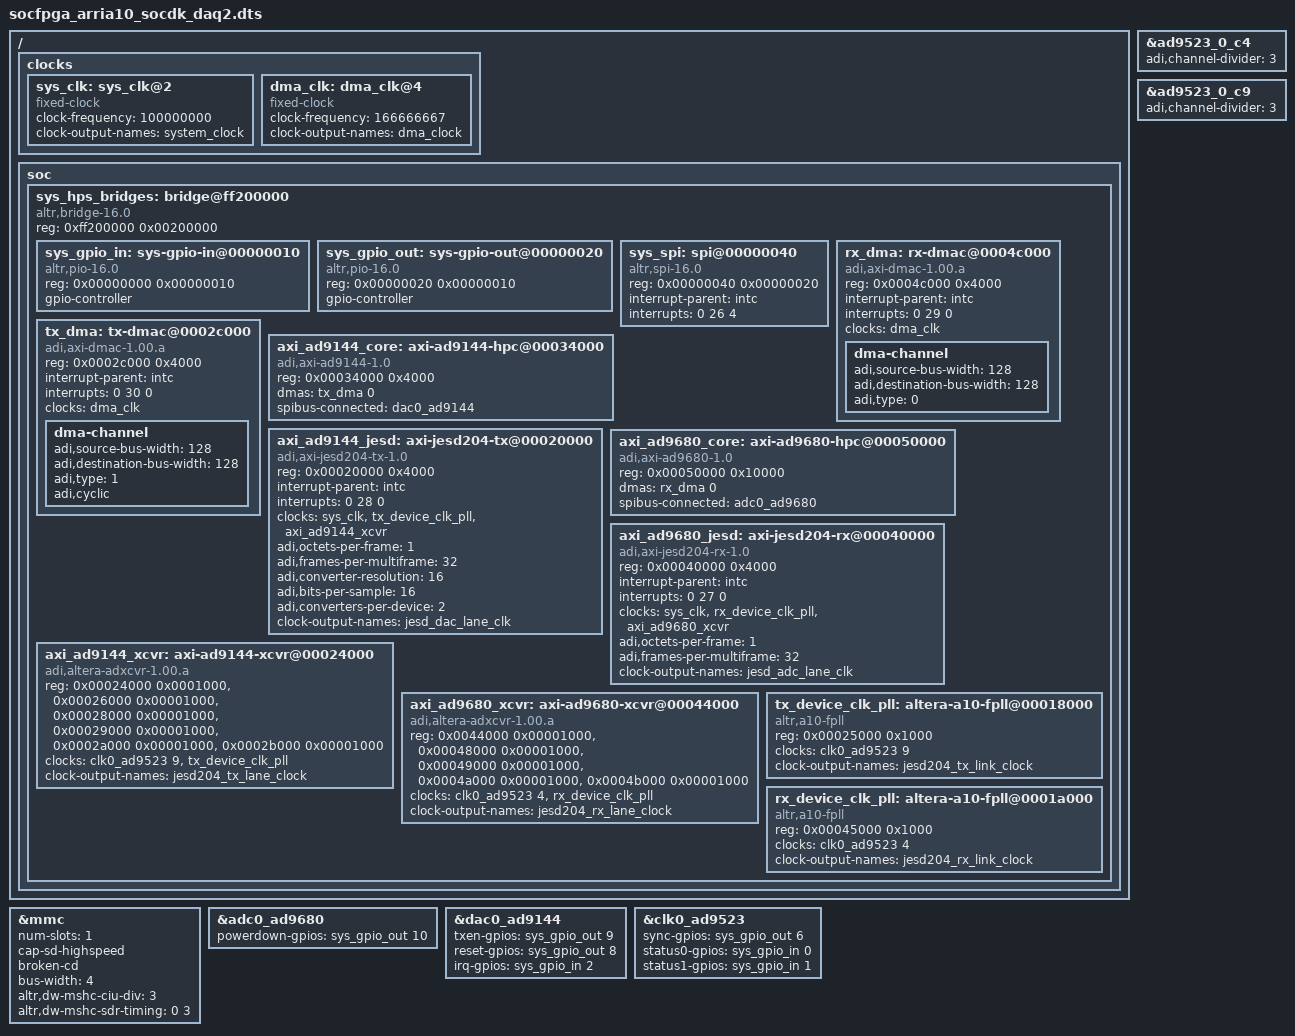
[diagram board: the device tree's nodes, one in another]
/dts-v1/;
#include "socfpga_arria10_socdk.dtsi"

&mmc {
	status = "okay";
	num-slots = <1>;
	cap-sd-highspeed;
	broken-cd;
	bus-width = <4>;
	altr,dw-mshc-ciu-div = <3>;
	altr,dw-mshc-sdr-timing = <0 3>;
};

/ {
	clocks {
		sys_clk: sys_clk@2 {
			#clock-cells = <0>;
			compatible = "fixed-clock";
			clock-frequency = <100000000>;
			clock-output-names = "system_clock";
		};

		dma_clk: dma_clk@4 {
			#clock-cells = <0>;
			compatible = "fixed-clock";
			clock-frequency = <166666667>;
			clock-output-names = "dma_clock";
		};
	};

	soc {
		sys_hps_bridges: bridge@ff200000 {
			compatible = "altr,bridge-16.0", "simple-bus";
			reg = <0xff200000 0x00200000>;
			#address-cells = <1>;
			#size-cells = <1>;
			ranges = <0x00000000 0xff200000 0x00200000>;

			sys_gpio_in: sys-gpio-in@00000010 {
				compatible = "altr,pio-16.0", "altr,pio-1.0";
				reg = <0x00000000 0x00000010>;
				#gpio-cells = <2>;
				gpio-controller;
			};

			sys_gpio_out: sys-gpio-out@00000020 {
				compatible = "altr,pio-16.0", "altr,pio-1.0";
				reg = <0x00000020 0x00000010>;
				#gpio-cells = <2>;
				gpio-controller;
			};

			sys_spi: spi@00000040 {
				compatible = "altr,spi-16.0", "altr,spi-1.0";
				reg = <0x00000040 0x00000020>;
				interrupt-parent = <&intc>;
				interrupts = <0 26 4>;
				#address-cells = <0x1>;
				#size-cells = <0x0>;
			};

			rx_dma: rx-dmac@0004c000 {
				compatible = "adi,axi-dmac-1.00.a";
				reg = <0x0004c000 0x4000>;
				#dma-cells = <1>;
				interrupt-parent = <&intc>;
				interrupts = <0 29 0>;
				clocks = <&dma_clk>;

				dma-channel {
					adi,source-bus-width = <128>;
					adi,destination-bus-width = <128>;
					adi,type = <0>;
				};
			};

			tx_dma: tx-dmac@0002c000 {
				compatible = "adi,axi-dmac-1.00.a";
				reg = <0x0002c000 0x4000>;
				#dma-cells = <1>;
				interrupt-parent = <&intc>;
				interrupts = <0 30 0>;
				clocks = <&dma_clk>;

				dma-channel {
					adi,source-bus-width = <128>;
					adi,destination-bus-width = <128>;
					adi,type = <1>;
					adi,cyclic;
				};
			};

			axi_ad9144_core: axi-ad9144-hpc@00034000 {
				compatible = "adi,axi-ad9144-1.0";
				reg = <0x00034000 0x4000>;
				dmas = <&tx_dma 0>;
				dma-names = "tx";
				spibus-connected = <&dac0_ad9144>;
//				adi,axi-pl-fifo-enable;
			};

			axi_ad9144_jesd: axi-jesd204-tx@00020000 {
				compatible = "adi,axi-jesd204-tx-1.0";
				reg = <0x00020000 0x4000>;

				interrupt-parent = <&intc>;
				interrupts = <0 28 0>;

				clocks = <&sys_clk>, <&tx_device_clk_pll>, <&axi_ad9144_xcvr>;
				clock-names = "s_axi_aclk", "device_clk", "lane_clk";

				adi,octets-per-frame = <1>;
				adi,frames-per-multiframe = <32>;
				adi,converter-resolution = <16>;
				adi,bits-per-sample = <16>;
				adi,converters-per-device = <2>;

				#clock-cells = <0>;
				clock-output-names = "jesd_dac_lane_clk";
			};

			axi_ad9680_core: axi-ad9680-hpc@00050000 {
				compatible = "adi,axi-ad9680-1.0";
				reg = <0x00050000 0x10000>;
				dmas = <&rx_dma 0>;
				dma-names = "rx";
				spibus-connected = <&adc0_ad9680>;
			};

			axi_ad9680_jesd: axi-jesd204-rx@00040000 {
				compatible = "adi,axi-jesd204-rx-1.0";
				reg = <0x00040000 0x4000>;

				interrupt-parent = <&intc>;
				interrupts = <0 27 0>;

				clocks = <&sys_clk>, <&rx_device_clk_pll>, <&axi_ad9680_xcvr>;
				clock-names = "s_axi_aclk", "device_clk", "lane_clk";

				adi,octets-per-frame = <1>;
				adi,frames-per-multiframe = <32>;

				#clock-cells = <0>;
				clock-output-names = "jesd_adc_lane_clk";
			};

			axi_ad9144_xcvr: axi-ad9144-xcvr@00024000 {
				compatible = "adi,altera-adxcvr-1.00.a";
				reg = <0x00024000 0x0001000>,
					<0x00026000 0x00001000>,
					<0x00028000 0x00001000>,
					<0x00029000 0x00001000>,
					<0x0002a000 0x00001000>,
					<0x0002b000 0x00001000>;
				reg-names = "adxcvr", "atx-pll", "adxcfg-0", "adxcfg-1", "adxcfg-2", "adxcfg-3";

				#clock-cells = <0>;
				clocks = <&clk0_ad9523 9>, <&tx_device_clk_pll>;
				clock-names = "ref", "link";
				clock-output-names = "jesd204_tx_lane_clock";
			};

			axi_ad9680_xcvr: axi-ad9680-xcvr@00044000 {
				compatible = "adi,altera-adxcvr-1.00.a";
				reg = <0x0044000 0x00001000>,
					<0x00048000 0x00001000>,
					<0x00049000 0x00001000>,
					<0x0004a000 0x00001000>,
					<0x0004b000 0x00001000>;
				reg-names = "adxcvr", "adxcfg-0", "adxcfg-1", "adxcfg-2", "adxcfg-3";

				#clock-cells = <0>;
				clocks = <&clk0_ad9523 4>, <&rx_device_clk_pll>;
				clock-names = "ref", "link";
				clock-output-names = "jesd204_rx_lane_clock";
			};

			tx_device_clk_pll: altera-a10-fpll@00018000 {
				compatible = "altr,a10-fpll";
				reg = <0x00025000 0x1000>;
				#clock-cells = <0>;
				clocks = <&clk0_ad9523 9>;
				clock-output-names = "jesd204_tx_link_clock";
			};

			rx_device_clk_pll: altera-a10-fpll@0001a000 {
				compatible = "altr,a10-fpll";
				reg = <0x00045000 0x1000>;
				#clock-cells = <0>;
				clocks = <&clk0_ad9523 4>;
				clock-output-names = "jesd204_rx_link_clock";
			};
		};
	};
};

#define fmc_spi sys_spi

#include "adi-daq2.dtsi"

&adc0_ad9680 {
	powerdown-gpios = <&sys_gpio_out 10 0>;
//	fastdetect-a-gpios = <&sys_gpio_in 4 0>;
//	fastdetect-b-gpios = <&sys_gpio_in 3 0>;
};

&dac0_ad9144 {
	txen-gpios = <&sys_gpio_out 9 0>;
	reset-gpios = <&sys_gpio_out 8 0>;
	irq-gpios = <&sys_gpio_in 2 0>;
};

&clk0_ad9523 {
	sync-gpios = <&sys_gpio_out 6 0>;
	status0-gpios = <&sys_gpio_in 0 0>;
	status1-gpios = <&sys_gpio_in 1 0>;
};

/*
 * Set FPGA ref clocks to 333.33 MHz. Allows to generate a wider range of lane
 * rates.
 */
&ad9523_0_c4 {
	adi,channel-divider = <3>;
};

&ad9523_0_c9 {
	adi,channel-divider = <3>;
};
